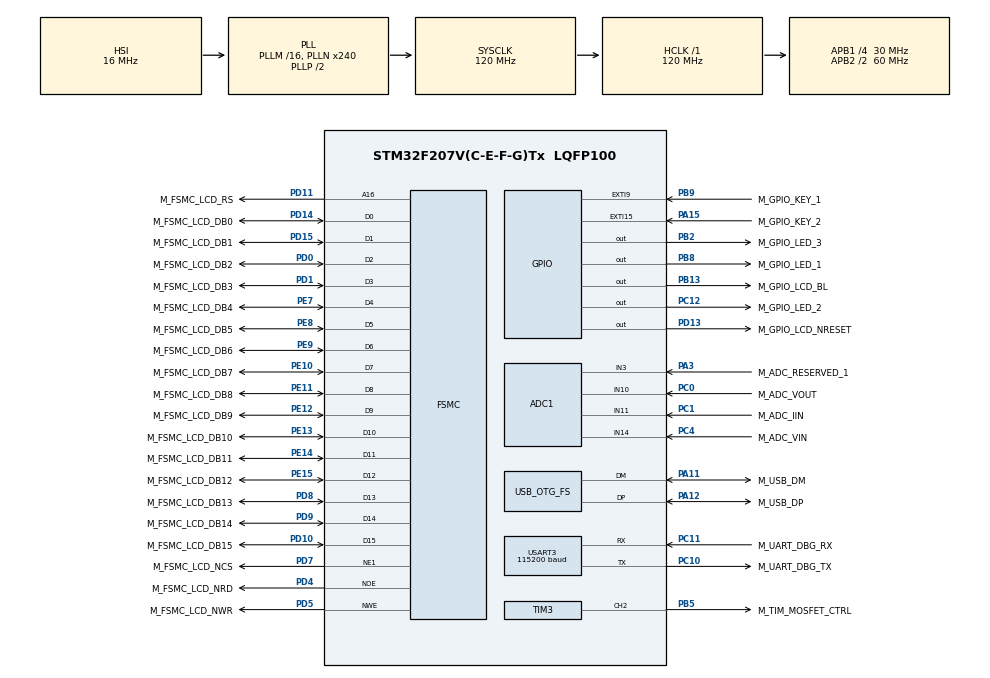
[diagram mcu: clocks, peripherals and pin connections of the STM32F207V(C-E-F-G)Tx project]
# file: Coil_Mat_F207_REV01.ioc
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ADC1.Channel-2\#ChannelRegularConversion=ADC_CHANNEL_14
ADC1.Channel-3\#ChannelRegularConversion=ADC_CHANNEL_10
ADC1.Channel-4\#ChannelRegularConversion=ADC_CHANNEL_11
ADC1.DMAContinuousRequests=ENABLE
ADC1.DiscontinuousConvMode=ENABLE
ADC1.ExternalTrigConv=ADC_EXTERNALTRIGCONV_T2_CC2
ADC1.NbrOfConversion=3
ADC1.NbrOfConversionFlag=1
ADC1.Rank-2\#ChannelRegularConversion=1
ADC1.Rank-3\#ChannelRegularConversion=2
ADC1.Rank-4\#ChannelRegularConversion=3
ADC1.SamplingTime-2\#ChannelRegularConversion=ADC_SAMPLETIME_3CYCLES
ADC1.SamplingTime-3\#ChannelRegularConversion=ADC_SAMPLETIME_3CYCLES
ADC1.SamplingTime-4\#ChannelRegularConversion=ADC_SAMPLETIME_3CYCLES
ADC1.master=1
Dma.ADC1.0.Direction=DMA_PERIPH_TO_MEMORY
Dma.ADC1.0.FIFOMode=DMA_FIFOMODE_DISABLE
Dma.ADC1.0.Instance=DMA2_Stream0
Dma.ADC1.0.MemDataAlignment=DMA_MDATAALIGN_WORD
Dma.ADC1.0.MemInc=DMA_MINC_ENABLE
Dma.ADC1.0.Mode=DMA_CIRCULAR
Dma.ADC1.0.PeriphDataAlignment=DMA_PDATAALIGN_WORD
Dma.ADC1.0.PeriphInc=DMA_PINC_DISABLE
Dma.ADC1.0.Priority=DMA_PRIORITY_LOW
Dma.Request0=ADC1
Dma.Request1=USART3_RX
Dma.USART3_RX.1.Direction=DMA_PERIPH_TO_MEMORY
Dma.USART3_RX.1.FIFOMode=DMA_FIFOMODE_DISABLE
Dma.USART3_RX.1.Instance=DMA1_Stream1
Dma.USART3_RX.1.MemDataAlignment=DMA_MDATAALIGN_BYTE
Dma.USART3_RX.1.MemInc=DMA_MINC_ENABLE
Dma.USART3_RX.1.Mode=DMA_CIRCULAR
Dma.USART3_RX.1.PeriphDataAlignment=DMA_PDATAALIGN_BYTE
Dma.USART3_RX.1.PeriphInc=DMA_PINC_DISABLE
Dma.USART3_RX.1.Priority=DMA_PRIORITY_LOW
FSMC.DataSetupTime1=35
Mcu.Family=STM32F2
Mcu.Name=STM32F207V(C-E-F-G)Tx
Mcu.Package=LQFP100
NVIC.ADC_IRQn=true\:0\:0\:false\:false\:true\:true\:true\:true
NVIC.DMA1_Stream1_IRQn=true\:0\:0\:false\:false\:true\:false\:true\:true
NVIC.DMA2_Stream0_IRQn=true\:0\:0\:false\:false\:true\:false\:true\:true
NVIC.EXTI15_10_IRQn=true\:0\:0\:false\:false\:true\:true\:true\:true
NVIC.EXTI9_5_IRQn=true\:0\:0\:false\:false\:true\:true\:true\:true
NVIC.OTG_FS_IRQn=true\:0\:0\:false\:false\:true\:false\:true\:true
NVIC.PriorityGroup=NVIC_PRIORITYGROUP_4
NVIC.TIM8_TRG_COM_TIM14_IRQn=true\:0\:0\:false\:false\:true\:true\:true\:true
PA11.GPIO_Label=M_USB_DM
PA11.Mode=Device_Only
PA11.Signal=USB_OTG_FS_DM
PA12.GPIO_Label=M_USB_DP
PA12.Mode=Device_Only
PA12.Signal=USB_OTG_FS_DP
PA13.GPIO_Label=M_SWDIO
PA13.Mode=Serial_Wire
PA13.Signal=SYS_JTMS-SWDIO
PA14.GPIO_Label=M_SWCLK
PA14.Mode=Serial_Wire
PA14.Signal=SYS_JTCK-SWCLK
PA15.GPIO_Label=M_GPIO_KEY_2
PA15.GPIO_ModeDefaultEXTI=GPIO_MODE_IT_FALLING
PA15.Signal=GPXTI15
PA3.GPIO_Label=M_ADC_RESERVED_1
PA3.Signal=ADCx_IN3
PB13.GPIO_Label=M_GPIO_LCD_BL
PB13.Signal=GPIO_Output
PB2.GPIO_Label=M_GPIO_LED_3
PB2.Signal=GPIO_Output
PB5.GPIO_Label=M_TIM_MOSFET_CTRL
PB5.Signal=S_TIM3_CH2
PB8.GPIO_Label=M_GPIO_LED_1
PB8.Signal=GPIO_Output
PB9.GPIO_Label=M_GPIO_KEY_1
PB9.GPIO_ModeDefaultEXTI=GPIO_MODE_IT_FALLING
PB9.Signal=GPXTI9
PC0.GPIO_Label=M_ADC_VOUT
PC0.Signal=ADCx_IN10
PC1.GPIO_Label=M_ADC_IIN
PC1.Signal=ADCx_IN11
PC10.GPIO_Label=M_UART_DBG_TX
PC10.Mode=Asynchronous
PC10.Signal=USART3_TX
PC11.GPIO_Label=M_UART_DBG_RX
PC11.Mode=Asynchronous
PC11.Signal=USART3_RX
PC12.GPIO_Label=M_GPIO_LED_2
PC12.Signal=GPIO_Output
PC4.GPIO_Label=M_ADC_VIN
PC4.Signal=ADCx_IN14
PD0.GPIO_Label=M_FSMC_LCD_DB2
PD0.Mode=16b-d1
PD0.Signal=FSMC_D2
PD1.GPIO_Label=M_FSMC_LCD_DB3
PD1.Mode=16b-d1
PD1.Signal=FSMC_D3
PD10.GPIO_Label=M_FSMC_LCD_DB15
PD10.Mode=16b-d1
PD10.Signal=FSMC_D15
PD11.GPIO_Label=M_FSMC_LCD_RS
PD11.Mode=A16_1
PD11.Signal=FSMC_A16
PD13.GPIO_Label=M_GPIO_LCD_NRESET
PD13.Signal=GPIO_Output
PD14.GPIO_Label=M_FSMC_LCD_DB0
PD14.Mode=16b-d1
PD14.Signal=FSMC_D0
PD15.GPIO_Label=M_FSMC_LCD_DB1
PD15.Mode=16b-d1
PD15.Signal=FSMC_D1
PD4.GPIO_Label=M_FSMC_LCD_NRD
PD4.Mode=Lcd1
PD4.Signal=FSMC_NOE
PD5.GPIO_Label=M_FSMC_LCD_NWR
PD5.Mode=Lcd1
PD5.Signal=FSMC_NWE
PD7.GPIO_Label=M_FSMC_LCD_NCS
PD7.Mode=NorPsramChipSelect1_1
PD7.Signal=FSMC_NE1
PD8.GPIO_Label=M_FSMC_LCD_DB13
PD8.Mode=16b-d1
PD8.Signal=FSMC_D13
PD9.GPIO_Label=M_FSMC_LCD_DB14
PD9.Mode=16b-d1
PD9.Signal=FSMC_D14
PE10.GPIO_Label=M_FSMC_LCD_DB7
PE10.Mode=16b-d1
PE10.Signal=FSMC_D7
PE11.GPIO_Label=M_FSMC_LCD_DB8
PE11.Mode=16b-d1
PE11.Signal=FSMC_D8
PE12.GPIO_Label=M_FSMC_LCD_DB9
PE12.Mode=16b-d1
PE12.Signal=FSMC_D9
PE13.GPIO_Label=M_FSMC_LCD_DB10
PE13.Mode=16b-d1
PE13.Signal=FSMC_D10
PE14.GPIO_Label=M_FSMC_LCD_DB11
PE14.Mode=16b-d1
PE14.Signal=FSMC_D11
PE15.GPIO_Label=M_FSMC_LCD_DB12
PE15.Mode=16b-d1
PE15.Signal=FSMC_D12
PE7.GPIO_Label=M_FSMC_LCD_DB4
PE7.Mode=16b-d1
PE7.Signal=FSMC_D4
PE8.GPIO_Label=M_FSMC_LCD_DB5
PE8.Mode=16b-d1
PE8.Signal=FSMC_D5
PE9.GPIO_Label=M_FSMC_LCD_DB6
PE9.Mode=16b-d1
PE9.Signal=FSMC_D6
ProjectManager.HeapSize=0x200
ProjectManager.StackSize=0x400
ProjectManager.TargetToolchain=STM32CubeIDE
RCC.48MHZClocksFreq_Value=48000000
RCC.AHBFreq_Value=120000000
RCC.APB1CLKDivider=RCC_HCLK_DIV4
RCC.APB1Freq_Value=30000000
RCC.APB1TimFreq_Value=60000000
RCC.APB2CLKDivider=RCC_HCLK_DIV2
RCC.APB2Freq_Value=60000000
RCC.APB2TimFreq_Value=120000000
RCC.CortexFreq_Value=120000000
RCC.HCLKFreq_Value=120000000
RCC.HSE_VALUE=8000000
RCC.HSI_VALUE=16000000
RCC.LSE_VALUE=32768
RCC.PLLN=240
RCC.PLLQ=5
RCC.SYSCLKFreq_VALUE=120000000
RCC.SYSCLKSource=RCC_SYSCLKSOURCE_PLLCLK
RCC.VCOOutputFreq_Value=240000000
SH.ADCx_IN10.0=ADC1_IN10,IN10
SH.ADCx_IN11.0=ADC1_IN11,IN11
SH.ADCx_IN14.0=ADC1_IN14,IN14
SH.ADCx_IN3.0=ADC1_IN3,IN3
SH.S_TIM3_CH2.0=TIM3_CH2,PWM Generation2 CH2
TIM14.ClockDivision=TIM_CLOCKDIVISION_DIV1
TIM14.Period=6000-1
TIM14.Prescaler=1-1
TIM2.Channel-PWM\ Generation2\ No\ Output=TIM_CHANNEL_2
TIM2.Period=1000-1
TIM2.Prescaler=12000-1
TIM2.Pulse-PWM\ Generation2\ No\ Output=700-1
TIM3.Channel-Output\ Compare1\ No\ Output=TIM_CHANNEL_1
TIM3.Channel-PWM\ Generation2\ CH2=TIM_CHANNEL_2
TIM3.ClockDivision=TIM_CLOCKDIVISION_DIV1
TIM3.Period=1000-1
TIM3.Prescaler=12000-1
TIM3.Pulse-Output\ Compare1\ No\ Output=690-1
TIM3.Pulse-PWM\ Generation2\ CH2=700-1
TIM3.TIM_MasterOutputTrigger=TIM_TRGO_OC1
TIM3.TIM_MasterSlaveMode=TIM_MASTERSLAVEMODE_ENABLE
USART3.BaudRate=115200
USART3.VirtualMode=VM_ASYNC
USB_DEVICE.CLASS_NAME_FS=CDC
USB_DEVICE.VirtualMode-CDC_FS=Cdc
USB_DEVICE.VirtualModeFS=Cdc_FS
USB_OTG_FS.Sof_enable=ENABLE
USB_OTG_FS.VirtualMode=Device_Only
VP_TIM14_VS_ClockSourceINT.Mode=Enable_Timer
VP_TIM2_VS_ClockSourceITR.Mode=TriggerSource_ITR2
VP_TIM2_VS_ControllerModeReset.Mode=Reset Mode
VP_TIM2_VS_no_output2.Mode=PWM Generation2 No Output
VP_TIM3_VS_ClockSourceINT.Mode=Internal
VP_TIM3_VS_no_output1.Mode=Output Compare1 No Output
VP_USB_DEVICE_VS_USB_DEVICE_CDC_FS.Mode=CDC_FS
board=custom

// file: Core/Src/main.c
/* USER CODE BEGIN Header */
/**
 ******************************************************************************
 * @file           : main.c
 * @brief          : Main program body
 ******************************************************************************
 * @attention
 *
 * Copyright (c) 2022 STMicroelectronics.
 * All rights reserved.
 *
 * This software is licensed under terms that can be found in the LICENSE file
 * in the root directory of this software component.
 * If no LICENSE file comes with this software, it is provided AS-IS.
 *
 ******************************************************************************
 */
/* USER CODE END Header */
#include "main.h"
#include "adc.h"
#include "dma.h"
#include "tim.h"
#include "usart.h"
#include "usb_device.h"
#include "gpio.h"
#include "fsmc.h"

/* USER CODE BEGIN Includes */
/***** skkim Code Begin *****/
#include "hw_def.h"
#include "user.h" //User Header
/***** skkim Code End *****/
/* USER CODE END Includes */

void SystemClock_Config(void);

int main(void)
{

  /* MCU Configuration--------------------------------------------------------*/

  /* Reset of all peripherals, Initializes the Flash interface and the Systick. */
  HAL_Init();

  /* Configure the system clock */
  SystemClock_Config();

  /* Initialize all configured peripherals */
  MX_GPIO_Init();
  MX_DMA_Init();
  MX_FSMC_Init();
  MX_USB_DEVICE_Init();
  MX_TIM3_Init();
  MX_USART3_UART_Init();
  MX_ADC1_Init();
  MX_TIM14_Init();
  MX_TIM2_Init();
  /* USER CODE BEGIN 2 */
  /***** skkim Code Begin *****/
  userInit();
  apInit();

  apMain();
  /***** skkim Code End *****/
  /* USER CODE END 2 */

  /* Infinite loop */
  while (1)
  {

  }
}

void SystemClock_Config(void)
{
  RCC_OscInitTypeDef RCC_OscInitStruct = {0};
  RCC_ClkInitTypeDef RCC_ClkInitStruct = {0};

  /** Initializes the RCC Oscillators according to the specified parameters
  * in the RCC_OscInitTypeDef structure.
  */
  RCC_OscInitStruct.OscillatorType = RCC_OSCILLATORTYPE_HSI;
  RCC_OscInitStruct.HSIState = RCC_HSI_ON;
  RCC_OscInitStruct.HSICalibrationValue = RCC_HSICALIBRATION_DEFAULT;
  RCC_OscInitStruct.PLL.PLLState = RCC_PLL_ON;
  RCC_OscInitStruct.PLL.PLLSource = RCC_PLLSOURCE_HSI;
  RCC_OscInitStruct.PLL.PLLM = 16;
  RCC_OscInitStruct.PLL.PLLN = 240;
  RCC_OscInitStruct.PLL.PLLP = RCC_PLLP_DIV2;
  RCC_OscInitStruct.PLL.PLLQ = 5;
  if (HAL_RCC_OscConfig(&RCC_OscInitStruct) != HAL_OK)
  {
    Error_Handler();
  }

  /** Initializes the CPU, AHB and APB buses clocks
  */
  RCC_ClkInitStruct.ClockType = RCC_CLOCKTYPE_HCLK|RCC_CLOCKTYPE_SYSCLK
                              |RCC_CLOCKTYPE_PCLK1|RCC_CLOCKTYPE_PCLK2;
  RCC_ClkInitStruct.SYSCLKSource = RCC_SYSCLKSOURCE_PLLCLK;
  RCC_ClkInitStruct.AHBCLKDivider = RCC_SYSCLK_DIV1;
  RCC_ClkInitStruct.APB1CLKDivider = RCC_HCLK_DIV4;
  RCC_ClkInitStruct.APB2CLKDivider = RCC_HCLK_DIV2;

  if (HAL_RCC_ClockConfig(&RCC_ClkInitStruct, FLASH_LATENCY_3) != HAL_OK)
  {
    Error_Handler();
  }
}

void Error_Handler(void)
{
	__disable_irq();
	while (1)
	{
	}
}
